# K210 register map
Vendor: Canaan Inc.; File version: 1.0
Registers are 32-bit, read-write, reset 0x0 unless marked. A register's access mark holds for its fields unless they carry their own. Offsets are from the block's base; [hi:lo] are bit positions; {n}, {i} and the like mark numbered series; 'fields as' and 'values as' point back to an identical list.

## SPI2 — Serial Peripheral Interface 2 (slave)
Base 0x50240000
Same registers: OTP 0x50420000
0x00 dummy — Dummy register: this peripheral is not implemented yet

## APU — Audio Processor
Base 0x50250200
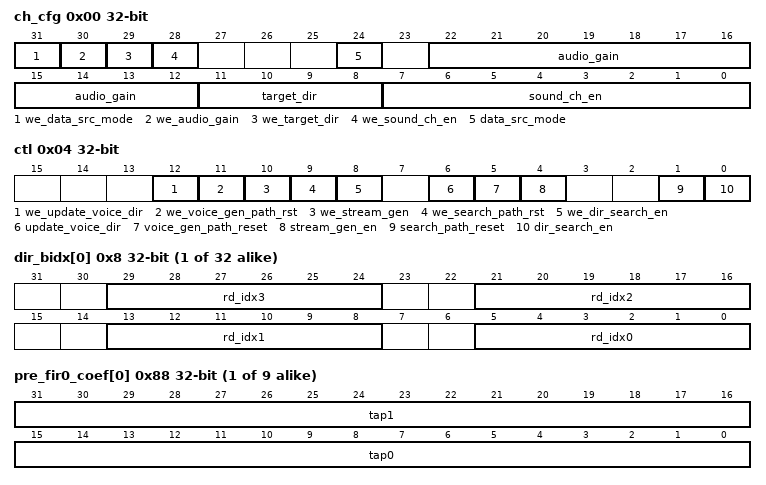
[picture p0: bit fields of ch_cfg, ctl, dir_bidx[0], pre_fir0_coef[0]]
0x00 ch_cfg — Channel Config Register
  [31] we_data_src_mode wo — Write enable for data_out_mode parameter
  [30] we_audio_gain wo — Write enable for audio_gain parameter
  [29] we_target_dir wo — Write enable for target_dir parameter
  [28] we_sound_ch_en wo — Write enable for sound_ch_en parameter
  [24] data_src_mode — Audio data source configure parameter
  [22:12] audio_gain — Audio sample gain factor
  [11:8] target_dir — Target direction select for valid voice output
  [7:0] sound_ch_en — BF unit sound channel enable control bits
0x04 ctl — Control Register
  [12] we_update_voice_dir wo — Write enable for we_update_voice_dir parameter
  [11] we_voice_gen_path_rst wo — Write enable for we_voice_gen_path_rst parameter
  [10] we_stream_gen wo — Write enable for we_stream_gen parameter
  [9] we_search_path_rst wo — Write enable for we_search_path_rst parameter
  [8] we_dir_search_en wo — Write enable for we_dir_search_en parameter
  [6] update_voice_dir — Switch to a new voice source direction
  [5] voice_gen_path_reset — Reset all control logic on voice stream generating path
  [4] stream_gen_en — Valid voice sample stream generation enable bit
  [1] search_path_reset — Reset all control logic on direction search processing path
  [0] dir_search_en — Sound direction searching enable bit
{0x8+4i} dir_bidx[{i}] (i=0..31) — Direction Sample Buffer Read Index Configure Register (16 directions * 2 values * 4 indices)
  [8n+5:8n] rd_idx{n} (n=0..3) — rd_idx{n}
{0x88+4i} pre_fir0_coef[{i}] (i=0..8) — FIR0 pre-filter coefficients
  [31:16] tap1, [15:0] tap0
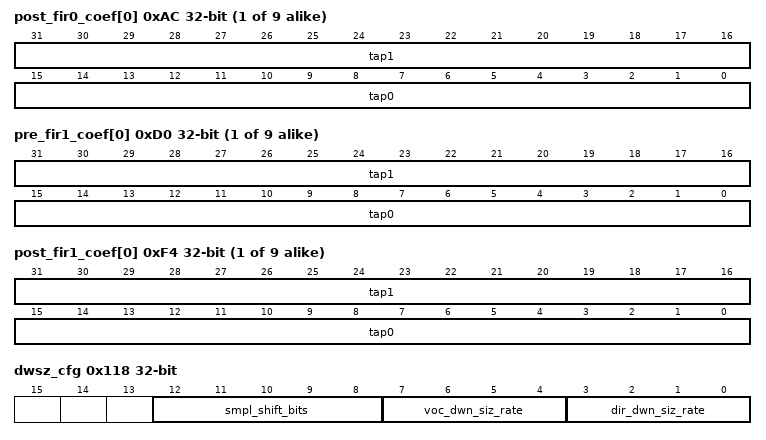
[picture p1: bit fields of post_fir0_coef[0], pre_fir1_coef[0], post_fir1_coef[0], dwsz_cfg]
{0xAC+4i} post_fir0_coef[{i}] (i=0..8) — FIR0 post-filter coefficients
  [31:16] tap1, [15:0] tap0
{0xD0+4i} pre_fir1_coef[{i}] (i=0..8) — FIR1 pre-filter coeffecients
  [31:16] tap1, [15:0] tap0
{0xF4+4i} post_fir1_coef[{i}] (i=0..8) — FIR1 post-filter coefficients
  [31:16] tap1, [15:0] tap0
0x118 dwsz_cfg — Downsize Config Register
  [12:8] smpl_shift_bits — Sample precision reduction when the source sound sample precision is 20/24/32 bits
  [7:4] voc_dwn_siz_rate — Down-sizing ratio used for voice stream generation
  [3:0] dir_dwn_siz_rate — Down-sizing ratio used for direction searching
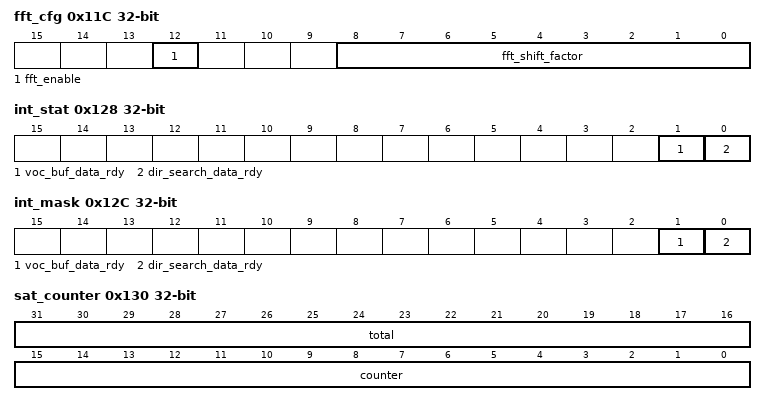
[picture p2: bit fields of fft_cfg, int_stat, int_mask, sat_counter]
0x11C fft_cfg — FFT Config Register
  [12] fft_enable, [8:0] fft_shift_factor
0x120 sobuf_dma_rdata — Read register for DMA to sample-out buffers
0x124 vobuf_dma_rdata — Read register for DMA to voice-out buffers
0x128 int_stat — Interrupt Status Register
  [1] voc_buf_data_rdy — Voice output stream buffer data ready interrupt event
  [0] dir_search_data_rdy — Sound direction searching data ready interrupt event
0x12C int_mask — Interrupt Mask Register
  fields as int_stat
0x130 sat_counter — Saturation Counter
  [31:16] total, [15:0] counter
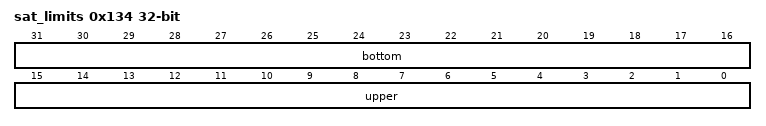
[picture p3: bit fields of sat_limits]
0x134 sat_limits — Saturation Limits
  [31:16] bottom — Bottom limit
  [15:0] upper — Upper limit

## I2C0 — Inter-Integrated Circuit Bus 0
Base 0x50280000
Same registers: I2C1 0x50290000, I2C2 0x502A0000
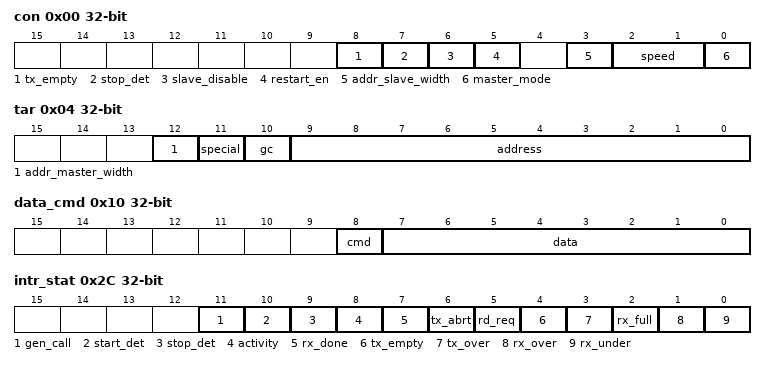
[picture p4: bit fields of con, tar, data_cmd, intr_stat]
0x00 con — Control Register
  [8] tx_empty — TX_EMPTY_CTRL
  [7] stop_det — STOP_DET_IFADDRESSED
  [6] slave_disable — Disable Slave
  [5] restart_en — Enable Restart
  [3] addr_slave_width — Slave address width
    0=b7 (7-bit address); 1=b10 (10-bit address)
  [2:1] speed
    0=standard; 1=fast; 2=highspeed
  [0] master_mode
0x04 tar — Target Address Register
  [12] addr_master_width — Master Address
    0=b7 (7-bit address); 1=b10 (10-bit address)
  [11] special
  [10] gc — GC_OR_START
  [9:0] address — Target Address
0x08 sar — Slave Address Register
  [9:0] address — Slave Address
0x10 data_cmd — Data Buffer and Command Register
  [8] cmd, [7:0] data
0x14 ss_scl_hcnt — Standard Speed Clock SCL High Count Register
  [15:0] count
0x18 ss_scl_lcnt — Standard Speed Clock SCL Low Count Register
  [15:0] count
0x2C intr_stat ro — Interrupt Status Register
  [11] gen_call, [10] start_det, [9] stop_det, [8] activity, [7] rx_done, [6] tx_abrt, [5] rd_req, [4] tx_empty, [3] tx_over, [2] rx_full, [1] rx_over, [0] rx_under
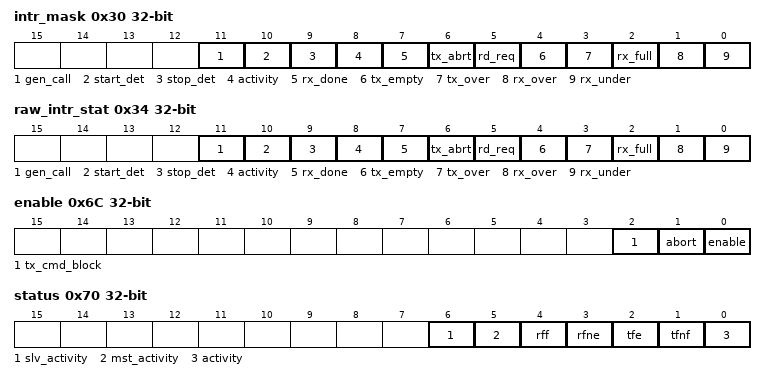
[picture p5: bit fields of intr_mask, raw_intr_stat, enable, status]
0x30 intr_mask — Interrupt Mask Register
  fields as intr_stat
0x34 raw_intr_stat — Raw Interrupt Status Register
  fields as intr_stat
0x38 rx_tl — Receive FIFO Threshold Register
  [2:0] value
0x3C tx_tl — Transmit FIFO Threshold Register
  [2:0] value
0x40 clr_intr ro — Clear Combined and Individual Interrupt Register
  [0] clr
0x44 clr_rx_under ro — Clear RX_UNDER Interrupt Register
  [0] clr
0x48 clr_rx_over ro — Clear RX_OVER Interrupt Register
  [0] clr
0x4C clr_tx_over ro — Clear TX_OVER Interrupt Register
  [0] clr
0x50 clr_rd_req ro — Clear RD_REQ Interrupt Register
  [0] clr
0x54 clr_tx_abrt ro — Clear TX_ABRT Interrupt Register
  [0] clr
0x58 clr_rx_done ro — Clear RX_DONE Interrupt Register
  [0] clr
0x5C clr_activity ro — Clear ACTIVITY Interrupt Register
  [0] clr
0x60 clr_stop_det ro — Clear STOP_DET Interrupt Register
  [0] clr
0x64 clr_start_det ro — Clear START_DET Interrupt Register
  [0] clr
0x68 clr_gen_call ro — I2C Clear GEN_CALL Interrupt Register
  [0] clr
0x6C enable
  [2] tx_cmd_block, [1] abort, [0] enable
0x70 status ro
  [6] slv_activity, [5] mst_activity, [4] rff, [3] rfne, [2] tfe, [1] tfnf, [0] activity
0x74 txflr — Transmit FIFO Level Register
  [2:0] value
0x78 rxflr — Receive FIFO Level Register
  [2:0] value
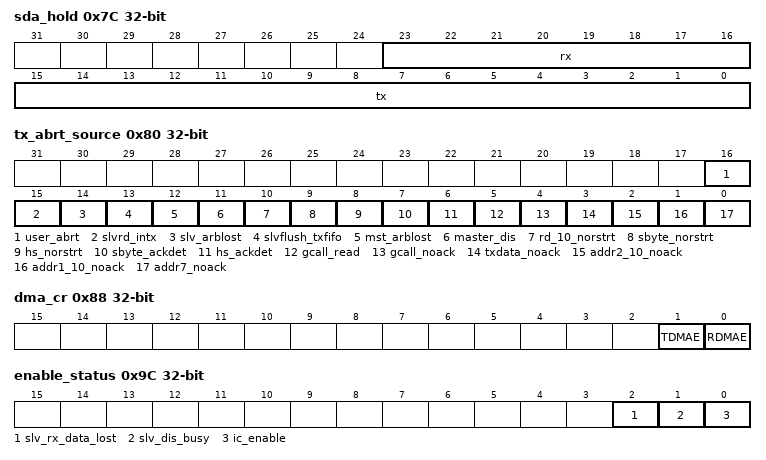
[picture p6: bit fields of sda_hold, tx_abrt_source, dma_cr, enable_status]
0x7C sda_hold — SDA Hold Time Length Register
  [23:16] rx, [15:0] tx
0x80 tx_abrt_source — Transmit Abort Source Register
  [16] user_abrt
  [15] slvrd_intx
  [14] slv_arblost
  [13] slvflush_txfifo
  [12] mst_arblost
  [11] master_dis
  [10] rd_10_norstrt — 10B_RD_NORSTRT
  [9] sbyte_norstrt
  [8] hs_norstrt
  [7] sbyte_ackdet
  [6] hs_ackdet
  [5] gcall_read
  [4] gcall_noack
  [3] txdata_noack
  [2] addr2_10_noack — 10B_ADDR2_NOACK
  [1] addr1_10_noack — 10B_ADDR1_NOACK
  [0] addr7_noack — 7B_ADDR_NOACK
0x88 dma_cr — I2C DMA Control Register
  [1] TDMAE, [0] RDMAE
0x8C dma_tdlr — DMA Transmit Data Level Register
  [2:0] value
0x90 dma_rdlr — DMA Receive Data Level Register
  [2:0] value
0x94 sda_setup
  [7:0] value
0x98 general_call — ACK General Call Register
  [0] call_enable
0x9C enable_status ro
  [2] slv_rx_data_lost, [1] slv_dis_busy, [0] ic_enable
0xA0 fs_spklen — SS, FS or FM+ spike suppression limit
  [7:0] value
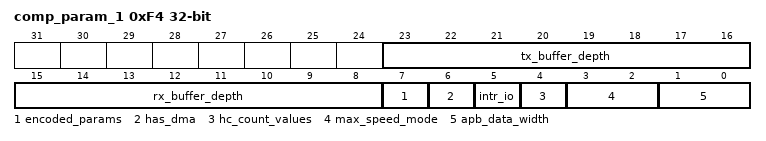
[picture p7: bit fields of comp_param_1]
0xF4 comp_param_1 ro — Component Parameter Register 1
  [23:16] tx_buffer_depth, [15:8] rx_buffer_depth, [7] encoded_params, [6] has_dma, [5] intr_io, [4] hc_count_values, [3:2] max_speed_mode, [1:0] apb_data_width
0xF8 comp_version ro — Component Version Register
  [31:0] value
0xFC comp_type ro — Component Type Register
  [31:0] value
